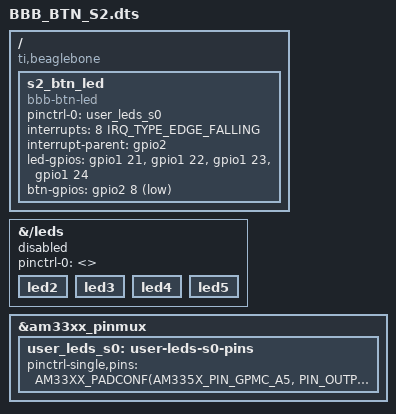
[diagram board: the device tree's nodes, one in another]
/dts-v1/;
/plugin/;

#include "dt-bindings/gpio/gpio.h"
#include "dt-bindings/pinctrl/am33xx.h"
#include "dt-bindings/interrupt-controller/irq.h"

/ {
	compatible = "ti,beaglebone", "ti,beaglebone-black", "ti,am335x-bone", "ti,am33xx";

	fragment@0 {
		target-path = "/leds";
		__overlay__ {
			compatible = "";
			pinctrl-names = "";
			pinctrl-0 = <>;
			status = "disabled";			
			led2 {};
			led3 {};
			led4 {};
			led5 {};
		};
	};

	fragment@1 {
		target = <&am33xx_pinmux>;
		__overlay__ {
			user_leds_s0: user-leds-s0-pins {
				pinctrl-single,pins = <
					AM33XX_PADCONF(AM335X_PIN_GPMC_A5, PIN_OUTPUT, MUX_MODE7)
					AM33XX_PADCONF(AM335X_PIN_GPMC_A6, PIN_OUTPUT, MUX_MODE7)
					AM33XX_PADCONF(AM335X_PIN_GPMC_A7, PIN_OUTPUT, MUX_MODE7)
					AM33XX_PADCONF(AM335X_PIN_GPMC_A8, PIN_OUTPUT, MUX_MODE7)
					AM33XX_PADCONF(AM335X_PIN_GPMC_A2, PIN_INPUT,  MUX_MODE7)
				>;
			};
		};
	};
	
	fragment@2 {
		target-path = "/";
		__overlay__ {
			s2_btn_led {
				compatible = "bbb-btn-led";
				pinctrl-names = "default";
				pinctrl-0 = <&user_leds_s0>;
				
				interrupts = <8 IRQ_TYPE_EDGE_FALLING>;
				interrupt-parent = <&gpio2>;

				led-gpios = <&gpio1 21 GPIO_ACTIVE_HIGH>,
							<&gpio1 22 GPIO_ACTIVE_HIGH>,
							<&gpio1 23 GPIO_ACTIVE_HIGH>,
							<&gpio1 24 GPIO_ACTIVE_HIGH>;
				btn-gpios = <&gpio2 8 GPIO_ACTIVE_LOW>;
			};
		};
	};
};
